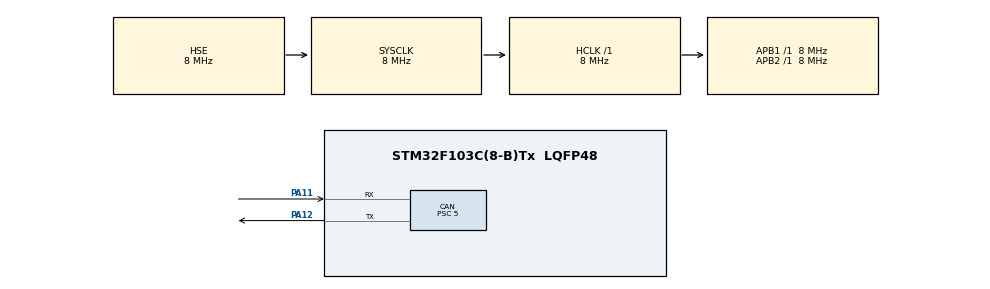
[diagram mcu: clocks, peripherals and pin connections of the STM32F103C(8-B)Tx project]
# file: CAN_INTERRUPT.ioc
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CAN.BS1=CAN_BS1_13TQ
CAN.BS2=CAN_BS2_2TQ
CAN.CalculateBaudRate=100000
CAN.CalculateTimeBit=10000.00
CAN.CalculateTimeQuantum=625.0
CAN.NART=ENABLE
CAN.Prescaler=5
Mcu.Family=STM32F1
Mcu.Name=STM32F103C(8-B)Tx
Mcu.Package=LQFP48
NVIC.PriorityGroup=NVIC_PRIORITYGROUP_4
PA11.Mode=CAN_Activate
PA11.Signal=CAN_RX
PA12.Mode=CAN_Activate
PA12.Signal=CAN_TX
PA13.Mode=Serial_Wire
PA13.Signal=SYS_JTMS-SWDIO
PA14.Mode=Serial_Wire
PA14.Signal=SYS_JTCK-SWCLK
PC14-OSC32_IN.Mode=LSE-External-Oscillator
PC14-OSC32_IN.Signal=RCC_OSC32_IN
PC15-OSC32_OUT.Mode=LSE-External-Oscillator
PC15-OSC32_OUT.Signal=RCC_OSC32_OUT
PD0-OSC_IN.Mode=HSE-External-Oscillator
PD0-OSC_IN.Signal=RCC_OSC_IN
PD1-OSC_OUT.Mode=HSE-External-Oscillator
PD1-OSC_OUT.Signal=RCC_OSC_OUT
ProjectManager.HeapSize=0x200
ProjectManager.StackSize=0x400
ProjectManager.TargetToolchain=MDK-ARM V5.27
RCC.AHBFreq_Value=8000000
RCC.APB1Freq_Value=8000000
RCC.APB1TimFreq_Value=8000000
RCC.APB2Freq_Value=8000000
RCC.APB2TimFreq_Value=8000000
RCC.HCLKFreq_Value=8000000
RCC.PLLMUL=RCC_PLL_MUL9
RCC.SYSCLKFreq_VALUE=8000000
RCC.SYSCLKSource=RCC_SYSCLKSOURCE_HSE
RCC.USBFreq_Value=36000000
board=custom

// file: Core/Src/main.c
/* USER CODE BEGIN Header */
/**
  ******************************************************************************
  * @file           : main.c
  * @brief          : Main program body
  ******************************************************************************
  * @attention
  *
  * <h2><center>&copy; Copyright (c) 2021 STMicroelectronics.
  * All rights reserved.</center></h2>
  *
  * This software component is licensed by ST under BSD 3-Clause license,
  * the "License"; You may not use this file except in compliance with the
  * License. You may obtain a copy of the License at:
  *                        opensource.org/licenses/BSD-3-Clause
  *
  ******************************************************************************
  */
/* USER CODE END Header */
#include "main.h"
#include "can.h"
#include "gpio.h"

void SystemClock_Config(void);
/* USER CODE BEGIN PFP */
HAL_StatusTypeDef CAN_Transmit(void);
HAL_StatusTypeDef CAN_Filter_Config( void );
/* USER CODE END PFP */

int main(void)
{

  /* MCU Configuration--------------------------------------------------------*/

  /* Reset of all peripherals, Initializes the Flash interface and the Systick. */
  HAL_Init();

  /* Configure the system clock */
  SystemClock_Config();

  /* Initialize all configured peripherals */
  MX_GPIO_Init();
  MX_CAN_Init();
  /* USER CODE BEGIN 2 */
	CAN_Filter_Config();
	if( HAL_OK != HAL_CAN_ActivateNotification(&hcan, CAN_IT_TX_MAILBOX_EMPTY | CAN_IT_RX_FIFO0_MSG_PENDING | CAN_IT_BUSOFF)){
		Error_Handler();
	}
	if( HAL_OK != HAL_CAN_Start(&hcan)){ // put can in normal mode
		Error_Handler();
	}
	CAN_Transmit();
  /* USER CODE END 2 */

  /* Infinite loop */
  while (1)
  {

  }
}

void SystemClock_Config(void)
{
  RCC_OscInitTypeDef RCC_OscInitStruct = {0};
  RCC_ClkInitTypeDef RCC_ClkInitStruct = {0};

  /** Initializes the RCC Oscillators according to the specified parameters
  * in the RCC_OscInitTypeDef structure.
  */
  RCC_OscInitStruct.OscillatorType = RCC_OSCILLATORTYPE_HSE;
  RCC_OscInitStruct.HSEState = RCC_HSE_ON;
  RCC_OscInitStruct.PLL.PLLState = RCC_PLL_NONE;
  if (HAL_RCC_OscConfig(&RCC_OscInitStruct) != HAL_OK)
  {
    Error_Handler();
  }
  /** Initializes the CPU, AHB and APB buses clocks
  */
  RCC_ClkInitStruct.ClockType = RCC_CLOCKTYPE_HCLK|RCC_CLOCKTYPE_SYSCLK
                              |RCC_CLOCKTYPE_PCLK1|RCC_CLOCKTYPE_PCLK2;
  RCC_ClkInitStruct.SYSCLKSource = RCC_SYSCLKSOURCE_HSE;
  RCC_ClkInitStruct.AHBCLKDivider = RCC_SYSCLK_DIV1;
  RCC_ClkInitStruct.APB1CLKDivider = RCC_HCLK_DIV1;
  RCC_ClkInitStruct.APB2CLKDivider = RCC_HCLK_DIV1;

  if (HAL_RCC_ClockConfig(&RCC_ClkInitStruct, FLASH_LATENCY_0) != HAL_OK)
  {
    Error_Handler();
  }
}

/* USER CODE BEGIN 4 */
HAL_StatusTypeDef CAN_Transmit(void){
	uint8_t msg[]= "hello";
	uint32_t mail_box;

	CAN_TxHeaderTypeDef Tx_header;
	Tx_header.DLC = 5u; // Transmit 5bytes "hello"
	Tx_header.IDE = CAN_ID_STD;
	Tx_header.StdId = 0x65D;
	Tx_header.RTR = CAN_RTR_DATA;

	if( HAL_OK != HAL_CAN_AddTxMessage(&hcan, &Tx_header, msg, &mail_box)){
		Error_Handler();
	}

	return HAL_OK;
}

HAL_StatusTypeDef CAN_Filter_Config( void ){
	CAN_FilterTypeDef Rx_filter_init;

	Rx_filter_init.FilterActivation = ENABLE;
	Rx_filter_init.FilterBank = 0U;
	Rx_filter_init.FilterFIFOAssignment = CAN_RX_FIFO0;
	Rx_filter_init.FilterIdHigh = 0x0000;
	Rx_filter_init.FilterIdLow = 0x0000;
	Rx_filter_init.FilterMaskIdHigh = 0x0000;
	Rx_filter_init.FilterMaskIdLow = 0x0000;
	Rx_filter_init.FilterMode = CAN_FILTERMODE_IDMASK;
	Rx_filter_init.FilterScale = CAN_FILTERSCALE_32BIT;

	HAL_CAN_ConfigFilter(&hcan, &Rx_filter_init);

	return HAL_OK;
}

void HAL_CAN_TxMailbox0CompleteCallback(CAN_HandleTypeDef *hcan){
  // completed transmition
}
void HAL_CAN_TxMailbox1CompleteCallback(CAN_HandleTypeDef *hcan){
	// completed transmition
}
void HAL_CAN_TxMailbox2CompleteCallback(CAN_HandleTypeDef *hcan){
	// completed transmition
}
void HAL_CAN_RxFifo0MsgPendingCallback(CAN_HandleTypeDef *hcan){
	CAN_RxHeaderTypeDef Rx_header;
	uint8_t buff[10u];

	/* get message into buff */
	if( HAL_OK != HAL_CAN_GetRxMessage(hcan, CAN_RX_FIFO0, &Rx_header, buff)){
		Error_Handler();
	}
}
void HAL_CAN_ErrorCallback(CAN_HandleTypeDef *hcan){
	// error happen
}

/* USER CODE END 4 */

void Error_Handler(void)
{
  __disable_irq();
  while (1)
  {
  }
}

/************************ (C) COPYRIGHT STMicroelectronics *****END OF FILE****/
